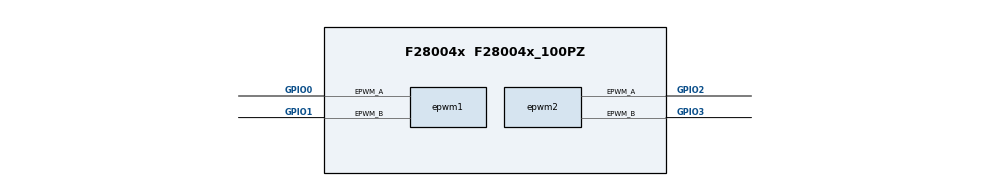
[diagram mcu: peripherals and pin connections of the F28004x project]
/**
 * These arguments were used when this file was generated. They will be automatically applied on subsequent loads
 * via the GUI or CLI. Run CLI with '--help' for additional information on how to override these arguments.
 * @cliArgs --device "F28004x" --package "F28004x_100PZ" --part "F28004x_100PZ" --context "system" --product "C2000WARE@4.03.00.00"
 * @versions {"tool":"1.16.1+2960"}
 */

/**
 * Import the modules used in this configuration.
 */
const epwm       = scripting.addModule("/driverlib/epwm.js", {}, false);
const epwm1      = epwm.addInstance();
const epwm2      = epwm.addInstance();
const epwm3      = epwm.addInstance();
const inputxbar  = scripting.addModule("/driverlib/inputxbar.js", {}, false);
const inputxbar1 = inputxbar.addInstance();

/**
 * Write custom configuration values to the imported modules.
 */
const multiplier2         = system.clockTree["PLL_IMULT"];
multiplier2.multiplyValue = 10;

epwm1.epwmTimebase_counterMode                                   = "EPWM_COUNTER_MODE_UP_DOWN";
epwm1.epwmTimebase_hsClockDiv                                    = "EPWM_HSCLOCK_DIVIDER_1";
epwm1.epwmActionQualifier_EPWM_AQ_OUTPUT_A_shadowMode            = true;
epwm1.epwmDeadband_enableRED                                     = true;
epwm1.epwmDeadband_enableFED                                     = true;
epwm1.epwmDeadband_delayRED                                      = 50;
epwm1.epwmDeadband_delayFED                                      = 50;
epwm1.epwmActionQualifier_EPWM_AQ_OUTPUT_A_ON_TIMEBASE_ZERO      = "EPWM_AQ_OUTPUT_HIGH";
epwm1.epwmActionQualifier_EPWM_AQ_OUTPUT_A_ON_TIMEBASE_UP_CMPA   = "EPWM_AQ_OUTPUT_LOW";
epwm1.epwmActionQualifier_EPWM_AQ_OUTPUT_A_ON_TIMEBASE_DOWN_CMPA = "EPWM_AQ_OUTPUT_HIGH";
epwm1.epwmActionQualifier_EPWM_AQ_OUTPUT_B_ON_TIMEBASE_UP_CMPB   = "EPWM_AQ_OUTPUT_HIGH";
epwm1.epwmActionQualifier_EPWM_AQ_OUTPUT_B_ON_TIMEBASE_DOWN_CMPB = "EPWM_AQ_OUTPUT_LOW";
epwm1.epwmEventTrigger_enableInterrupt                           = true;
epwm1.epwmEventTrigger_interruptSource                           = "EPWM_INT_TBCTR_ZERO";
epwm1.$name                                                      = "myEPWM1";
epwm1.epwmTimebase_period                                        = 2500;
epwm1.epwmEventTrigger_interruptEventCount                       = "1";
epwm1.epwm.$assign                                               = "EPWM1";
epwm1.epwm.epwm_aPin.$assign                                     = "GPIO0";
epwm1.epwm.epwm_bPin.$assign                                     = "GPIO1";

epwm2.epwmTimebase_period                                        = 2499;
epwm2.epwmTimebase_counterValue                                  = 500;
epwm2.epwmTimebase_counterMode                                   = "EPWM_COUNTER_MODE_UP_DOWN";
epwm2.epwmActionQualifier_EPWM_AQ_OUTPUT_A_shadowMode            = true;
epwm2.epwmActionQualifier_EPWM_AQ_OUTPUT_B_shadowMode            = true;
epwm2.epwmDeadband_enableRED                                     = true;
epwm2.epwmDeadband_enableFED                                     = true;
epwm2.epwmDeadband_redShadowMode                                 = true;
epwm2.epwmDeadband_fedShadowMode                                 = true;
epwm2.epwmDeadband_outputSwapOutA                                = true;
epwm2.epwmDeadband_outputSwapOutB                                = true;
epwm2.epwmDeadband_delayRED                                      = 50;
epwm2.epwmDeadband_delayFED                                      = 50;
epwm2.epwmActionQualifier_EPWM_AQ_OUTPUT_A_ON_TIMEBASE_ZERO      = "EPWM_AQ_OUTPUT_HIGH";
epwm2.epwmActionQualifier_EPWM_AQ_OUTPUT_A_ON_TIMEBASE_UP_CMPA   = "EPWM_AQ_OUTPUT_LOW";
epwm2.epwmActionQualifier_EPWM_AQ_OUTPUT_A_ON_TIMEBASE_DOWN_CMPA = "EPWM_AQ_OUTPUT_HIGH";
epwm2.epwmActionQualifier_EPWM_AQ_OUTPUT_B_ON_TIMEBASE_UP_CMPB   = "EPWM_AQ_OUTPUT_HIGH";
epwm2.epwmActionQualifier_EPWM_AQ_OUTPUT_B_ON_TIMEBASE_DOWN_CMPB = "EPWM_AQ_OUTPUT_LOW";
epwm2.epwmEventTrigger_enableInterrupt                           = true;
epwm2.epwmEventTrigger_interruptEventCount                       = "1";
epwm2.epwmEventTrigger_interruptSource                           = "EPWM_INT_TBCTR_ZERO";
epwm2.$name                                                      = "myEPWM2";
epwm2.epwm.$assign                                               = "EPWM2";
epwm2.epwm.epwm_aPin.$assign                                     = "GPIO2";
epwm2.epwm.epwm_bPin.$assign                                     = "GPIO3";

epwm3.epwmTimebase_hsClockDiv                                    = "EPWM_HSCLOCK_DIVIDER_1";
epwm3.epwmTimebase_period                                        = 2499;
epwm3.epwmTimebase_counterValue                                  = 500;
epwm3.epwmCounterCompare_cmpA                                    = 250;
epwm3.epwmActionQualifier_EPWM_AQ_OUTPUT_A_shadowMode            = true;
epwm3.epwmDeadband_enableRED                                     = true;
epwm3.epwmDeadband_enableFED                                     = true;
epwm3.epwmDeadband_redShadowMode                                 = true;
epwm3.epwmDeadband_fedShadowMode                                 = true;
epwm3.epwmDeadband_inputFED                                      = "EPWM_DB_INPUT_EPWMB";
epwm3.epwmDeadband_delayRED                                      = 50;
epwm3.epwmDeadband_delayFED                                      = 50;
epwm3.epwmActionQualifier_EPWM_AQ_OUTPUT_A_ON_TIMEBASE_ZERO      = "EPWM_AQ_OUTPUT_HIGH";
epwm3.epwmActionQualifier_EPWM_AQ_OUTPUT_A_ON_TIMEBASE_UP_CMPA   = "EPWM_AQ_OUTPUT_LOW";
epwm3.epwmActionQualifier_EPWM_AQ_OUTPUT_A_ON_TIMEBASE_DOWN_CMPA = "EPWM_AQ_OUTPUT_HIGH";
epwm3.epwmActionQualifier_EPWM_AQ_OUTPUT_B_ON_TIMEBASE_UP_CMPB   = "EPWM_AQ_OUTPUT_HIGH";
epwm3.epwmActionQualifier_EPWM_AQ_OUTPUT_B_ON_TIMEBASE_DOWN_CMPB = "EPWM_AQ_OUTPUT_LOW";
epwm3.$name                                                      = "myEPWM3";

inputxbar1.$name = "myINPUTXBAR0";

/**
 * Pinmux solution for unlocked pins/peripherals. This ensures that minor changes to the automatic solver in a future
 * version of the tool will not impact the pinmux you originally saw.  These lines can be completely deleted in order to
 * re-solve from scratch.
 */
epwm3.epwm.$suggestSolution           = "EPWM3";
epwm3.epwm.epwm_aPin.$suggestSolution = "GPIO4";
epwm3.epwm.epwm_bPin.$suggestSolution = "GPIO5";
